# MCASP1_AFIFO register map
Vendor: Texas Instruments
Peripheral module from a debugger description file (folder DRA74xP_75xP_76xP_77xP).
Registers are 32-bit, read-only, reset values left out (the file's numbers can be read two ways) unless marked. A register's access mark holds for its fields unless they carry their own. Offsets are as the file gives them; lines under a group give offsets from that group; [hi:lo] are bit positions; {n}, {i} and the like mark numbered series; 'fields as' and 'values as' point back to an identical list; <NAME> marks a mode.

## MCASP1_AFIFO
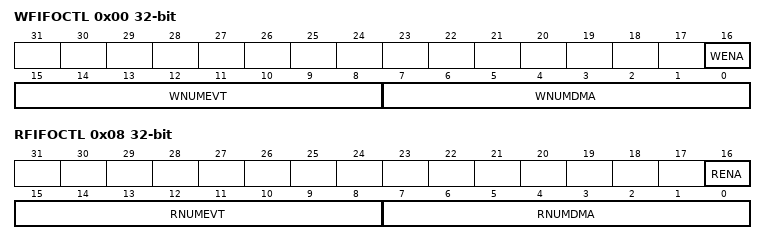
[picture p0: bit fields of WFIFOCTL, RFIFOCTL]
0x00 WFIFOCTL access per field — The Write FIFO control register. The WNUMEVT and WNUMDMA values must be set prior to enabling the Write FIFO. If the Write FIFO is to be enabled, it must be enabled prior to taking the MCASP out of reset.
  [16] WENA rw — Write FIFO enable bit.
    0=FIFO_FIFO_MCASP_DMA_FIFO_WLVL_FIFO_0 (Write FIFO is disabled (default). Data access by the host must pass through the FIFO block to the MCASP transparently. DMA requests must also pass through the FIFO block transparently. WLVL is reset to 0 and pointers are initialized, i.e., the write FIFO is “flushed.”); 1=FIFO_FIFO_MCASP._1 (Write FIFO is enabled.If write FIFO is to be enabled, it must be enabled prior to enabling MCASP.)
  [15:8] WNUMEVT rw — Write word count (32-bit) to generate TX event to host. When Write FIFO has word space for more or equal to this value then transmit event will be generated to host/DMA.This value must be set prior to enabling the write FIFO.0x3 - 0x40: 3 to 64 words currently in write FIFO. . 0x41 - 0xFF: Reserved. .
    0=0_words; 1=1_word; 2=2_words
  [7:0] WNUMDMA rw — Write word count (32-bit words). On the transmit DMA event from MCASP the WNUMDMA word will be transferred from DMA engine to MCASP. This value must equal the number of MCASP serializers used as transmitters.This value must be set prior to enabling the write FIFO.0x3 - 0x10: 3 to 16 words. . 0x11 - 0xFF: Reserved. .
    0=0_words; 1=1_word; 2=2_words
0x04 WFIFOSTS — The Write FIFO status register.
  [7:0] WLVL — Write level (read-only). Number of 32-bit words currently in write FIFO.0x3 - 0x40: 3 to 64 words currently in write FIFO. . 0x41 - 0xFF: Reserved. .
    0=0_words_currently_in_write_FIFO; 1=1_word_currently_in_write_FIFO; 2=2_words_currently_in_write_FIFO
0x08 RFIFOCTL access not given — The Read FIFO control register. The RNUMEVT and RNUMDMA values must be set prior to enabling the Read FIFO. If the Read FIFO is to be enabled, it must be enabled prior to taking the MCASP out of reset.
  [16] RENA rw — Read FIFO enable bit.
    0=FIFO_FIFO_MCASP_DMA_FIFO_RLVL_FIFO_0 (Read FIFO is disabled (default). Data access by the host must pass through the FIFO block to the MCASP transparently. DMA requests must also pass through the FIFO block transparently. RLVL is reset to 0 and pointers are initialized, i.e., the read FIFO is “flushed.”); 1=FIFO_FIFO_MCASP._1 (Read FIFO is enabled.If read FIFO is to be enabled, it must be enabled prior to enabling MCASP.)
  [15:8] RNUMEVT rw — Read word count (32-bit) to generate RX event to host. When Read FIFO has number of word available which is more or equal to this value then receive event will be generated to host/DMA.This value must be set prior to enabling the write FIFO.0x3 - 0x40: 3 to 64 words currently in read FIFO. . 0x41 - 0xFF: Reserved .
    0=0_words_currently_in_read_FIFO; 1=1_word_currently_in_read_FIFO; 2=2_words_currently_in_read_FIFO
  [7:0] RNUMDMA — Read word count (32-bit words). On receive DMA event from MCASP, the DMA engine will read specified number of words from MCASP. This value must equal the number of MCASP serializers used as transmitters.This value must be set prior to enabling the read FIFO.0x3 - 0x10: 3-16 words . 0x11 - 0xFF: Reserved .
    0=0_words; 1=1_word; 2=2_words
0x0C RFIFOSTS — The Read FIFO status register
  [7:0] RLVL — Read level (read-only). Number of 32-bit words currently in read FIFO.0x3 - 0x40: 3 to 64 words currently in read FIFO. . 0x41 - 0xFF: Reserved. .
    values as RFIFOCTL.RNUMEVT
